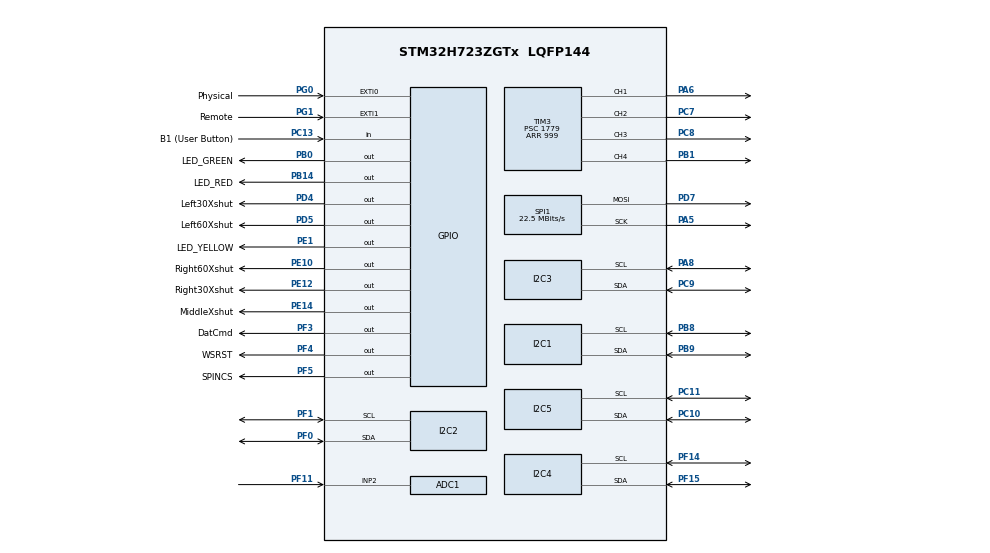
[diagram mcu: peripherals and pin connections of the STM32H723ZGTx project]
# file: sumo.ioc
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ADC1.Channel-0\#ChannelRegularConversion=ADC_CHANNEL_2
ADC1.NbrOfConversionFlag=1
ADC1.OffsetNumber-0\#ChannelRegularConversion=ADC_OFFSET_NONE
ADC1.OffsetSignedSaturation-0\#ChannelRegularConversion=DISABLE
ADC1.Rank-0\#ChannelRegularConversion=1
ADC1.SamplingTime-0\#ChannelRegularConversion=ADC_SAMPLETIME_1CYCLE_5
ADC1.master=1
CORTEX_M7.default_mode_Activation=1
I2C1.Timing=0x207077AF
I2C2.Timing=0x207077AF
I2C3.Timing=0x207077AF
I2C4.Timing=0x207077AF
I2C5.Timing=0x207077AF
Mcu.Family=STM32H7
Mcu.Name=STM32H723ZGTx
Mcu.Package=LQFP144
NVIC.ADC_IRQn=true\:0\:0\:false\:false\:true\:true\:true\:true
NVIC.EXTI0_IRQn=true\:0\:0\:false\:false\:true\:true\:true\:true
NVIC.EXTI1_IRQn=true\:0\:0\:false\:false\:true\:true\:true\:true
NVIC.PriorityGroup=NVIC_PRIORITYGROUP_4
PA13(JTMS/SWDIO).GPIO_Label=SWDIO
PA13(JTMS/SWDIO).Signal=DEBUG_JTMS-SWDIO
PA14(JTCK/SWCLK).GPIO_Label=SWCLK
PA14(JTCK/SWCLK).Signal=DEBUG_JTCK-SWCLK
PA5.Mode=TX_Only_Simplex_Unidirect_Master
PA5.Signal=SPI1_SCK
PA6.Signal=S_TIM3_CH1
PA8.Mode=I2C
PA8.Signal=I2C3_SCL
PB0.GPIO_Label=LED_GREEN
PB0.Signal=GPIO_Output
PB1.Signal=S_TIM3_CH4
PB14.GPIO_Label=LED_RED
PB14.Signal=GPIO_Output
PB8.Mode=I2C
PB8.Signal=I2C1_SCL
PB9.Mode=I2C
PB9.Signal=I2C1_SDA
PC10.Mode=I2C
PC10.Signal=I2C5_SDA
PC11.Mode=I2C
PC11.Signal=I2C5_SCL
PC13.GPIO_Label=B1 (User Button)
PC13.Signal=GPIO_Input
PC14-OSC32_IN.Signal=RCC_OSC32_IN
PC15-OSC32_OUT.Signal=RCC_OSC32_OUT
PC7.Signal=S_TIM3_CH2
PC8.Signal=S_TIM3_CH3
PC9.Mode=I2C
PC9.Signal=I2C3_SDA
PD4.GPIO_Label=Left30Xshut
PD4.PinState=GPIO_PIN_SET
PD4.Signal=GPIO_Output
PD5.GPIO_Label=Left60Xshut
PD5.PinState=GPIO_PIN_SET
PD5.Signal=GPIO_Output
PD7.Mode=TX_Only_Simplex_Unidirect_Master
PD7.Signal=SPI1_MOSI
PD8.GPIO_Label=STLK_VCP_RX
PD8.Signal=USART3_TX
PD9.GPIO_Label=STLK_VCP_TX
PD9.Signal=USART3_RX
PE1.GPIO_Label=LED_YELLOW
PE1.Signal=GPIO_Output
PE10.GPIO_Label=Right60Xshut
PE10.PinState=GPIO_PIN_SET
PE10.Signal=GPIO_Output
PE12.GPIO_Label=Right30Xshut
PE12.PinState=GPIO_PIN_SET
PE12.Signal=GPIO_Output
PE14.GPIO_Label=MiddleXshut
PE14.PinState=GPIO_PIN_SET
PE14.Signal=GPIO_Output
PF0.Mode=I2C
PF0.Signal=I2C2_SDA
PF1.Mode=I2C
PF1.Signal=I2C2_SCL
PF11.Mode=IN2-Single-Ended
PF11.Signal=ADC1_INP2
PF14.Mode=I2C
PF14.Signal=I2C4_SCL
PF15.Mode=I2C
PF15.Signal=I2C4_SDA
PF3.GPIO_Label=DatCmd
PF3.Signal=GPIO_Output
PF4.GPIO_Label=WSRST
PF4.Signal=GPIO_Output
PF5.GPIO_Label=SPINCS
PF5.Signal=GPIO_Output
PG0.GPIO_Label=Physical
PG0.GPIO_ModeDefaultEXTI=GPIO_MODE_IT_FALLING
PG0.GPIO_PuPd=GPIO_PULLDOWN
PG0.Signal=GPXTI0
PG1.GPIO_Label=Remote
PG1.GPIO_ModeDefaultEXTI=GPIO_MODE_IT_RISING_FALLING
PG1.GPIO_PuPd=GPIO_PULLDOWN
PG1.Signal=GPXTI1
PH0-OSC_IN.Mode=HSE-External-Oscillator
PH0-OSC_IN.Signal=RCC_OSC_IN
PH1-OSC_OUT.Mode=HSE-External-Oscillator
PH1-OSC_OUT.Signal=RCC_OSC_OUT
ProjectManager.HeapSize=0x200
ProjectManager.StackSize=0x400
ProjectManager.TargetToolchain=STM32CubeIDE
RCC.ADCFreq_Value=10000000
RCC.APB1Freq_Value=90000000
RCC.APB2Freq_Value=90000000
RCC.APB3Freq_Value=90000000
RCC.APB4Freq_Value=90000000
RCC.CortexFreq_Value=360000000
RCC.D1PPRE=RCC_APB3_DIV2
RCC.D2PPRE1=RCC_APB1_DIV2
RCC.D2PPRE2=RCC_APB2_DIV2
RCC.D3PPRE=RCC_APB4_DIV2
RCC.DIVM1=1
RCC.DIVM2=1
RCC.DIVN1=45
RCC.DIVN2=25
RCC.DIVP1=1
RCC.DIVP2=20
RCC.HCLKFreq_Value=180000000
RCC.HPRE=RCC_HCLK_DIV2
RCC.HSE_VALUE=8000000
RCC.PLL2FRACN=0
RCC.PLLFRACN=0
RCC.PLLSourceVirtual=RCC_PLLSOURCE_HSE
RCC.SYSCLKFreq_VALUE=360000000
RCC.SYSCLKSource=RCC_SYSCLKSOURCE_PLLCLK
RCC.USBCLockSelection=RCC_USBCLKSOURCE_HSI48
RCC.USBFreq_Value=48000000
SH.S_TIM3_CH1.0=TIM3_CH1,PWM Generation1 CH1
SH.S_TIM3_CH2.0=TIM3_CH2,PWM Generation2 CH2
SH.S_TIM3_CH3.0=TIM3_CH3,PWM Generation3 CH3
SH.S_TIM3_CH4.0=TIM3_CH4,PWM Generation4 CH4
SPI1.BaudRatePrescaler=SPI_BAUDRATEPRESCALER_8
SPI1.CalculateBaudRate=22.5 MBits/s
SPI1.DataSize=SPI_DATASIZE_8BIT
SPI1.Direction=SPI_DIRECTION_2LINES_TXONLY
SPI1.Mode=SPI_MODE_MASTER
SPI1.VirtualType=VM_MASTER
TIM3.Channel-PWM\ Generation1\ CH1=TIM_CHANNEL_1
TIM3.Channel-PWM\ Generation2\ CH2=TIM_CHANNEL_2
TIM3.Channel-PWM\ Generation3\ CH3=TIM_CHANNEL_3
TIM3.Channel-PWM\ Generation4\ CH4=TIM_CHANNEL_4
TIM3.Period=999
TIM3.Prescaler=1779
VP_MEMORYMAP_VS_MEMORYMAP.Mode=CurAppReg
VP_TIM3_VS_ClockSourceINT.Mode=Internal
board=NUCLEO-H723ZG

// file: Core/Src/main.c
/* USER CODE BEGIN Header */
/**
  ******************************************************************************
  * @file           : main.c
  * @brief          : Main program body
  ******************************************************************************
  * @attention
  *
  * Copyright (c) 2025 STMicroelectronics.
  * All rights reserved.
  *
  * This software is licensed under terms that can be found in the LICENSE file
  * in the root directory of this software component.
  * If no LICENSE file comes with this software, it is provided AS-IS.
  *
  ******************************************************************************
  */
/* USER CODE END Header */
#include "main.h"

/* USER CODE BEGIN PTD */
#include "../Repo/Inc/cpp_main.h"
/* USER CODE END PTD */

I2C_HandleTypeDef hi2c1;
I2C_HandleTypeDef hi2c2;
I2C_HandleTypeDef hi2c3;
I2C_HandleTypeDef hi2c4;
I2C_HandleTypeDef hi2c5;

SPI_HandleTypeDef hspi1;

void SystemClock_Config(void);
static void MPU_Config(void);
static void MX_GPIO_Init(void);
static void MX_ADC1_Init(void);
static void MX_I2C1_Init(void);
static void MX_I2C2_Init(void);
static void MX_I2C3_Init(void);
static void MX_I2C4_Init(void);
static void MX_I2C5_Init(void);
static void MX_SPI1_Init(void);
static void MX_TIM3_Init(void);

int main(void)
{

  /* MPU Configuration--------------------------------------------------------*/
  MPU_Config();

  /* MCU Configuration--------------------------------------------------------*/

  /* Reset of all peripherals, Initializes the Flash interface and the Systick. */
  HAL_Init();

  /* Configure the system clock */
  SystemClock_Config();

  /* Initialize all configured peripherals */
  MX_GPIO_Init();
  MX_ADC1_Init();
  MX_I2C1_Init();
  MX_I2C2_Init();
  MX_I2C3_Init();
  MX_I2C4_Init();
  MX_I2C5_Init();
  MX_SPI1_Init();
  MX_TIM3_Init();

  /* Infinite loop */
  /* USER CODE BEGIN WHILE */
  main_cpp_loop();
  while (1)
  {
    /* USER CODE END WHILE */

  }
}

void SystemClock_Config(void)
{
  RCC_OscInitTypeDef RCC_OscInitStruct = {0};
  RCC_ClkInitTypeDef RCC_ClkInitStruct = {0};

  /** Supply configuration update enable
  */
  HAL_PWREx_ConfigSupply(PWR_LDO_SUPPLY);

  /** Configure the main internal regulator output voltage
  */
  __HAL_PWR_VOLTAGESCALING_CONFIG(PWR_REGULATOR_VOLTAGE_SCALE1);

  while(!__HAL_PWR_GET_FLAG(PWR_FLAG_VOSRDY)) {}

  /** Initializes the RCC Oscillators according to the specified parameters
  * in the RCC_OscInitTypeDef structure.
  */
  RCC_OscInitStruct.OscillatorType = RCC_OSCILLATORTYPE_HSE;
  RCC_OscInitStruct.HSEState = RCC_HSE_ON;
  RCC_OscInitStruct.PLL.PLLState = RCC_PLL_ON;
  RCC_OscInitStruct.PLL.PLLSource = RCC_PLLSOURCE_HSE;
  RCC_OscInitStruct.PLL.PLLM = 1;
  RCC_OscInitStruct.PLL.PLLN = 45;
  RCC_OscInitStruct.PLL.PLLP = 1;
  RCC_OscInitStruct.PLL.PLLQ = 2;
  RCC_OscInitStruct.PLL.PLLR = 2;
  RCC_OscInitStruct.PLL.PLLRGE = RCC_PLL1VCIRANGE_3;
  RCC_OscInitStruct.PLL.PLLVCOSEL = RCC_PLL1VCOWIDE;
  RCC_OscInitStruct.PLL.PLLFRACN = 0;
  if (HAL_RCC_OscConfig(&RCC_OscInitStruct) != HAL_OK)
  {
    Error_Handler();
  }

  /** Initializes the CPU, AHB and APB buses clocks
  */
  RCC_ClkInitStruct.ClockType = RCC_CLOCKTYPE_HCLK|RCC_CLOCKTYPE_SYSCLK
                              |RCC_CLOCKTYPE_PCLK1|RCC_CLOCKTYPE_PCLK2
                              |RCC_CLOCKTYPE_D3PCLK1|RCC_CLOCKTYPE_D1PCLK1;
  RCC_ClkInitStruct.SYSCLKSource = RCC_SYSCLKSOURCE_PLLCLK;
  RCC_ClkInitStruct.SYSCLKDivider = RCC_SYSCLK_DIV1;
  RCC_ClkInitStruct.AHBCLKDivider = RCC_HCLK_DIV2;
  RCC_ClkInitStruct.APB3CLKDivider = RCC_APB3_DIV2;
  RCC_ClkInitStruct.APB1CLKDivider = RCC_APB1_DIV2;
  RCC_ClkInitStruct.APB2CLKDivider = RCC_APB2_DIV2;
  RCC_ClkInitStruct.APB4CLKDivider = RCC_APB4_DIV2;

  if (HAL_RCC_ClockConfig(&RCC_ClkInitStruct, FLASH_LATENCY_2) != HAL_OK)
  {
    Error_Handler();
  }
}

static void MX_ADC1_Init(void)
{

  LL_ADC_InitTypeDef ADC_InitStruct = {0};
  LL_ADC_REG_InitTypeDef ADC_REG_InitStruct = {0};
  LL_ADC_CommonInitTypeDef ADC_CommonInitStruct = {0};

  LL_GPIO_InitTypeDef GPIO_InitStruct = {0};
  RCC_PeriphCLKInitTypeDef PeriphClkInitStruct = {0};

  /** Initializes the peripherals clock
  */
  PeriphClkInitStruct.PeriphClockSelection = RCC_PERIPHCLK_ADC;
  PeriphClkInitStruct.PLL2.PLL2M = 1;
  PeriphClkInitStruct.PLL2.PLL2N = 25;
  PeriphClkInitStruct.PLL2.PLL2P = 20;
  PeriphClkInitStruct.PLL2.PLL2Q = 2;
  PeriphClkInitStruct.PLL2.PLL2R = 2;
  PeriphClkInitStruct.PLL2.PLL2RGE = RCC_PLL2VCIRANGE_3;
  PeriphClkInitStruct.PLL2.PLL2VCOSEL = RCC_PLL2VCOWIDE;
  PeriphClkInitStruct.PLL2.PLL2FRACN = 0.0;
  PeriphClkInitStruct.AdcClockSelection = RCC_ADCCLKSOURCE_PLL2;
  if (HAL_RCCEx_PeriphCLKConfig(&PeriphClkInitStruct) != HAL_OK)
  {
    Error_Handler();
  }

  /* Peripheral clock enable */
  LL_AHB1_GRP1_EnableClock(LL_AHB1_GRP1_PERIPH_ADC12);

  LL_AHB4_GRP1_EnableClock(LL_AHB4_GRP1_PERIPH_GPIOF);
  /**ADC1 GPIO Configuration
  PF11   ------> ADC1_INP2
  */
  GPIO_InitStruct.Pin = LL_GPIO_PIN_11;
  GPIO_InitStruct.Mode = LL_GPIO_MODE_ANALOG;
  GPIO_InitStruct.Pull = LL_GPIO_PULL_NO;
  LL_GPIO_Init(GPIOF, &GPIO_InitStruct);

  /* ADC1 interrupt Init */
  NVIC_SetPriority(ADC_IRQn, NVIC_EncodePriority(NVIC_GetPriorityGrouping(),0, 0));
  NVIC_EnableIRQ(ADC_IRQn);

  /** Common config
  */
  LL_ADC_SetOverSamplingScope(ADC1, LL_ADC_OVS_DISABLE);
  ADC_InitStruct.Resolution = LL_ADC_RESOLUTION_16B;
  ADC_InitStruct.LowPowerMode = LL_ADC_LP_MODE_NONE;
  LL_ADC_Init(ADC1, &ADC_InitStruct);
  ADC_REG_InitStruct.TriggerSource = LL_ADC_REG_TRIG_SOFTWARE;
  ADC_REG_InitStruct.SequencerLength = LL_ADC_REG_SEQ_SCAN_DISABLE;
  ADC_REG_InitStruct.SequencerDiscont = DISABLE;
  ADC_REG_InitStruct.ContinuousMode = LL_ADC_REG_CONV_SINGLE;
  ADC_REG_InitStruct.Overrun = LL_ADC_REG_OVR_DATA_PRESERVED;
  LL_ADC_REG_Init(ADC1, &ADC_REG_InitStruct);
  LL_ADC_REG_SetDataTransferMode(ADC1, LL_ADC_REG_DR_TRANSFER);
  ADC_CommonInitStruct.CommonClock = LL_ADC_CLOCK_ASYNC_DIV1;
  ADC_CommonInitStruct.Multimode = LL_ADC_MULTI_INDEPENDENT;
  LL_ADC_CommonInit(__LL_ADC_COMMON_INSTANCE(ADC1), &ADC_CommonInitStruct);

  /* Disable ADC deep power down (enabled by default after reset state) */
  LL_ADC_DisableDeepPowerDown(ADC1);
  /* Enable ADC internal voltage regulator */
  LL_ADC_EnableInternalRegulator(ADC1);
  /* Delay for ADC internal voltage regulator stabilization. */
  /* Compute number of CPU cycles to wait for, from delay in us. */
  /* Note: Variable divided by 2 to compensate partially */
  /* CPU processing cycles (depends on compilation optimization). */
  /* Note: If system core clock frequency is below 200kHz, wait time */
  /* is only a few CPU processing cycles. */
  __IO uint32_t wait_loop_index;
  wait_loop_index = ((LL_ADC_DELAY_INTERNAL_REGUL_STAB_US * (SystemCoreClock / (100000 * 2))) / 10);
  while(wait_loop_index != 0)
  {
    wait_loop_index--;
  }

  /** Configure Regular Channel
  */
  LL_ADC_REG_SetSequencerRanks(ADC1, LL_ADC_REG_RANK_1, LL_ADC_CHANNEL_2);
  LL_ADC_SetChannelSamplingTime(ADC1, LL_ADC_CHANNEL_2, LL_ADC_SAMPLINGTIME_1CYCLE_5);
  LL_ADC_SetChannelSingleDiff(ADC1, LL_ADC_CHANNEL_2, LL_ADC_SINGLE_ENDED);
  LL_ADC_SetChannelPreselection(ADC1, LL_ADC_CHANNEL_2);

}

static void MX_I2C1_Init(void)
{

  hi2c1.Instance = I2C1;
  hi2c1.Init.Timing = 0x207077AF;
  hi2c1.Init.OwnAddress1 = 0;
  hi2c1.Init.AddressingMode = I2C_ADDRESSINGMODE_7BIT;
  hi2c1.Init.DualAddressMode = I2C_DUALADDRESS_DISABLE;
  hi2c1.Init.OwnAddress2 = 0;
  hi2c1.Init.OwnAddress2Masks = I2C_OA2_NOMASK;
  hi2c1.Init.GeneralCallMode = I2C_GENERALCALL_DISABLE;
  hi2c1.Init.NoStretchMode = I2C_NOSTRETCH_DISABLE;
  if (HAL_I2C_Init(&hi2c1) != HAL_OK)
  {
    Error_Handler();
  }

  /** Configure Analogue filter
  */
  if (HAL_I2CEx_ConfigAnalogFilter(&hi2c1, I2C_ANALOGFILTER_ENABLE) != HAL_OK)
  {
    Error_Handler();
  }

  /** Configure Digital filter
  */
  if (HAL_I2CEx_ConfigDigitalFilter(&hi2c1, 0) != HAL_OK)
  {
    Error_Handler();
  }

}

static void MX_I2C2_Init(void)
{

  hi2c2.Instance = I2C2;
  hi2c2.Init.Timing = 0x207077AF;
  hi2c2.Init.OwnAddress1 = 0;
  hi2c2.Init.AddressingMode = I2C_ADDRESSINGMODE_7BIT;
  hi2c2.Init.DualAddressMode = I2C_DUALADDRESS_DISABLE;
  hi2c2.Init.OwnAddress2 = 0;
  hi2c2.Init.OwnAddress2Masks = I2C_OA2_NOMASK;
  hi2c2.Init.GeneralCallMode = I2C_GENERALCALL_DISABLE;
  hi2c2.Init.NoStretchMode = I2C_NOSTRETCH_DISABLE;
  if (HAL_I2C_Init(&hi2c2) != HAL_OK)
  {
    Error_Handler();
  }

  /** Configure Analogue filter
  */
  if (HAL_I2CEx_ConfigAnalogFilter(&hi2c2, I2C_ANALOGFILTER_ENABLE) != HAL_OK)
  {
    Error_Handler();
  }

  /** Configure Digital filter
  */
  if (HAL_I2CEx_ConfigDigitalFilter(&hi2c2, 0) != HAL_OK)
  {
    Error_Handler();
  }

}

static void MX_I2C3_Init(void)
{

  hi2c3.Instance = I2C3;
  hi2c3.Init.Timing = 0x207077AF;
  hi2c3.Init.OwnAddress1 = 0;
  hi2c3.Init.AddressingMode = I2C_ADDRESSINGMODE_7BIT;
  hi2c3.Init.DualAddressMode = I2C_DUALADDRESS_DISABLE;
  hi2c3.Init.OwnAddress2 = 0;
  hi2c3.Init.OwnAddress2Masks = I2C_OA2_NOMASK;
  hi2c3.Init.GeneralCallMode = I2C_GENERALCALL_DISABLE;
  hi2c3.Init.NoStretchMode = I2C_NOSTRETCH_DISABLE;
  if (HAL_I2C_Init(&hi2c3) != HAL_OK)
  {
    Error_Handler();
  }

  /** Configure Analogue filter
  */
  if (HAL_I2CEx_ConfigAnalogFilter(&hi2c3, I2C_ANALOGFILTER_ENABLE) != HAL_OK)
  {
    Error_Handler();
  }

  /** Configure Digital filter
  */
  if (HAL_I2CEx_ConfigDigitalFilter(&hi2c3, 0) != HAL_OK)
  {
    Error_Handler();
  }

}

static void MX_I2C4_Init(void)
{

  hi2c4.Instance = I2C4;
  hi2c4.Init.Timing = 0x207077AF;
  hi2c4.Init.OwnAddress1 = 0;
  hi2c4.Init.AddressingMode = I2C_ADDRESSINGMODE_7BIT;
  hi2c4.Init.DualAddressMode = I2C_DUALADDRESS_DISABLE;
  hi2c4.Init.OwnAddress2 = 0;
  hi2c4.Init.OwnAddress2Masks = I2C_OA2_NOMASK;
  hi2c4.Init.GeneralCallMode = I2C_GENERALCALL_DISABLE;
  hi2c4.Init.NoStretchMode = I2C_NOSTRETCH_DISABLE;
  if (HAL_I2C_Init(&hi2c4) != HAL_OK)
  {
    Error_Handler();
  }

  /** Configure Analogue filter
  */
  if (HAL_I2CEx_ConfigAnalogFilter(&hi2c4, I2C_ANALOGFILTER_ENABLE) != HAL_OK)
  {
    Error_Handler();
  }

  /** Configure Digital filter
  */
  if (HAL_I2CEx_ConfigDigitalFilter(&hi2c4, 0) != HAL_OK)
  {
    Error_Handler();
  }

}

static void MX_I2C5_Init(void)
{

  hi2c5.Instance = I2C5;
  hi2c5.Init.Timing = 0x207077AF;
  hi2c5.Init.OwnAddress1 = 0;
  hi2c5.Init.AddressingMode = I2C_ADDRESSINGMODE_7BIT;
  hi2c5.Init.DualAddressMode = I2C_DUALADDRESS_DISABLE;
  hi2c5.Init.OwnAddress2 = 0;
  hi2c5.Init.OwnAddress2Masks = I2C_OA2_NOMASK;
  hi2c5.Init.GeneralCallMode = I2C_GENERALCALL_DISABLE;
  hi2c5.Init.NoStretchMode = I2C_NOSTRETCH_DISABLE;
  if (HAL_I2C_Init(&hi2c5) != HAL_OK)
  {
    Error_Handler();
  }

  /** Configure Analogue filter
  */
  if (HAL_I2CEx_ConfigAnalogFilter(&hi2c5, I2C_ANALOGFILTER_ENABLE) != HAL_OK)
  {
    Error_Handler();
  }

  /** Configure Digital filter
  */
  if (HAL_I2CEx_ConfigDigitalFilter(&hi2c5, 0) != HAL_OK)
  {
    Error_Handler();
  }

}

static void MX_SPI1_Init(void)
{

  /* SPI1 parameter configuration*/
  hspi1.Instance = SPI1;
  hspi1.Init.Mode = SPI_MODE_MASTER;
  hspi1.Init.Direction = SPI_DIRECTION_2LINES_TXONLY;
  hspi1.Init.DataSize = SPI_DATASIZE_8BIT;
  hspi1.Init.CLKPolarity = SPI_POLARITY_LOW;
  hspi1.Init.CLKPhase = SPI_PHASE_1EDGE;
  hspi1.Init.NSS = SPI_NSS_SOFT;
  hspi1.Init.BaudRatePrescaler = SPI_BAUDRATEPRESCALER_8;
  hspi1.Init.FirstBit = SPI_FIRSTBIT_MSB;
  hspi1.Init.TIMode = SPI_TIMODE_DISABLE;
  hspi1.Init.CRCCalculation = SPI_CRCCALCULATION_DISABLE;
  hspi1.Init.CRCPolynomial = 0x0;
  hspi1.Init.NSSPMode = SPI_NSS_PULSE_ENABLE;
  hspi1.Init.NSSPolarity = SPI_NSS_POLARITY_LOW;
  hspi1.Init.FifoThreshold = SPI_FIFO_THRESHOLD_01DATA;
  hspi1.Init.TxCRCInitializationPattern = SPI_CRC_INITIALIZATION_ALL_ZERO_PATTERN;
  hspi1.Init.RxCRCInitializationPattern = SPI_CRC_INITIALIZATION_ALL_ZERO_PATTERN;
  hspi1.Init.MasterSSIdleness = SPI_MASTER_SS_IDLENESS_00CYCLE;
  hspi1.Init.MasterInterDataIdleness = SPI_MASTER_INTERDATA_IDLENESS_00CYCLE;
  hspi1.Init.MasterReceiverAutoSusp = SPI_MASTER_RX_AUTOSUSP_DISABLE;
  hspi1.Init.MasterKeepIOState = SPI_MASTER_KEEP_IO_STATE_DISABLE;
  hspi1.Init.IOSwap = SPI_IO_SWAP_DISABLE;
  if (HAL_SPI_Init(&hspi1) != HAL_OK)
  {
    Error_Handler();
  }

}

static void MX_TIM3_Init(void)
{

  LL_TIM_InitTypeDef TIM_InitStruct = {0};
  LL_TIM_OC_InitTypeDef TIM_OC_InitStruct = {0};

  LL_GPIO_InitTypeDef GPIO_InitStruct = {0};

  /* Peripheral clock enable */
  LL_APB1_GRP1_EnableClock(LL_APB1_GRP1_PERIPH_TIM3);

  TIM_InitStruct.Prescaler = 1779;
  TIM_InitStruct.CounterMode = LL_TIM_COUNTERMODE_UP;
  TIM_InitStruct.Autoreload = 999;
  TIM_InitStruct.ClockDivision = LL_TIM_CLOCKDIVISION_DIV1;
  LL_TIM_Init(TIM3, &TIM_InitStruct);
  LL_TIM_DisableARRPreload(TIM3);
  LL_TIM_SetClockSource(TIM3, LL_TIM_CLOCKSOURCE_INTERNAL);
  LL_TIM_OC_EnablePreload(TIM3, LL_TIM_CHANNEL_CH1);
  TIM_OC_InitStruct.OCMode = LL_TIM_OCMODE_PWM1;
  TIM_OC_InitStruct.OCState = LL_TIM_OCSTATE_DISABLE;
  TIM_OC_InitStruct.OCNState = LL_TIM_OCSTATE_DISABLE;
  TIM_OC_InitStruct.CompareValue = 0;
  TIM_OC_InitStruct.OCPolarity = LL_TIM_OCPOLARITY_HIGH;
  LL_TIM_OC_Init(TIM3, LL_TIM_CHANNEL_CH1, &TIM_OC_InitStruct);
  LL_TIM_OC_DisableFast(TIM3, LL_TIM_CHANNEL_CH1);
  LL_TIM_OC_EnablePreload(TIM3, LL_TIM_CHANNEL_CH2);
  LL_TIM_OC_Init(TIM3, LL_TIM_CHANNEL_CH2, &TIM_OC_InitStruct);
  LL_TIM_OC_DisableFast(TIM3, LL_TIM_CHANNEL_CH2);
  LL_TIM_OC_EnablePreload(TIM3, LL_TIM_CHANNEL_CH3);
  LL_TIM_OC_Init(TIM3, LL_TIM_CHANNEL_CH3, &TIM_OC_InitStruct);
  LL_TIM_OC_DisableFast(TIM3, LL_TIM_CHANNEL_CH3);
  LL_TIM_OC_EnablePreload(TIM3, LL_TIM_CHANNEL_CH4);
  LL_TIM_OC_Init(TIM3, LL_TIM_CHANNEL_CH4, &TIM_OC_InitStruct);
  LL_TIM_OC_DisableFast(TIM3, LL_TIM_CHANNEL_CH4);
  LL_TIM_SetTriggerOutput(TIM3, LL_TIM_TRGO_RESET);
  LL_TIM_DisableMasterSlaveMode(TIM3);
  LL_AHB4_GRP1_EnableClock(LL_AHB4_GRP1_PERIPH_GPIOA);
  LL_AHB4_GRP1_EnableClock(LL_AHB4_GRP1_PERIPH_GPIOB);
  LL_AHB4_GRP1_EnableClock(LL_AHB4_GRP1_PERIPH_GPIOC);
  /**TIM3 GPIO Configuration
  PA6   ------> TIM3_CH1
  PB1   ------> TIM3_CH4
  PC7   ------> TIM3_CH2
  PC8   ------> TIM3_CH3
  */
  GPIO_InitStruct.Pin = LL_GPIO_PIN_6;
  GPIO_InitStruct.Mode = LL_GPIO_MODE_ALTERNATE;
  GPIO_InitStruct.Speed = LL_GPIO_SPEED_FREQ_LOW;
  GPIO_InitStruct.OutputType = LL_GPIO_OUTPUT_PUSHPULL;
  GPIO_InitStruct.Pull = LL_GPIO_PULL_NO;
  GPIO_InitStruct.Alternate = LL_GPIO_AF_2;
  LL_GPIO_Init(GPIOA, &GPIO_InitStruct);

  GPIO_InitStruct.Pin = LL_GPIO_PIN_1;
  GPIO_InitStruct.Mode = LL_GPIO_MODE_ALTERNATE;
  GPIO_InitStruct.Speed = LL_GPIO_SPEED_FREQ_LOW;
  GPIO_InitStruct.OutputType = LL_GPIO_OUTPUT_PUSHPULL;
  GPIO_InitStruct.Pull = LL_GPIO_PULL_NO;
  GPIO_InitStruct.Alternate = LL_GPIO_AF_2;
  LL_GPIO_Init(GPIOB, &GPIO_InitStruct);

  GPIO_InitStruct.Pin = LL_GPIO_PIN_7|LL_GPIO_PIN_8;
  GPIO_InitStruct.Mode = LL_GPIO_MODE_ALTERNATE;
  GPIO_InitStruct.Speed = LL_GPIO_SPEED_FREQ_LOW;
  GPIO_InitStruct.OutputType = LL_GPIO_OUTPUT_PUSHPULL;
  GPIO_InitStruct.Pull = LL_GPIO_PULL_NO;
  GPIO_InitStruct.Alternate = LL_GPIO_AF_2;
  LL_GPIO_Init(GPIOC, &GPIO_InitStruct);

}

static void MX_GPIO_Init(void)
{
  GPIO_InitTypeDef GPIO_InitStruct = {0};

  /* GPIO Ports Clock Enable */
  __HAL_RCC_GPIOC_CLK_ENABLE();
  __HAL_RCC_GPIOF_CLK_ENABLE();
  __HAL_RCC_GPIOH_CLK_ENABLE();
  __HAL_RCC_GPIOA_CLK_ENABLE();
  __HAL_RCC_GPIOB_CLK_ENABLE();
  __HAL_RCC_GPIOG_CLK_ENABLE();
  __HAL_RCC_GPIOE_CLK_ENABLE();
  __HAL_RCC_GPIOD_CLK_ENABLE();

  /*Configure GPIO pin Output Level */
  HAL_GPIO_WritePin(GPIOF, DatCmd_Pin|WSRST_Pin|SPINCS_Pin, GPIO_PIN_RESET);

  /*Configure GPIO pin Output Level */
  HAL_GPIO_WritePin(GPIOB, LED_GREEN_Pin|LED_RED_Pin, GPIO_PIN_RESET);

  /*Configure GPIO pin Output Level */
  HAL_GPIO_WritePin(GPIOE, Right60Xshut_Pin|Right30Xshut_Pin|MiddleXshut_Pin, GPIO_PIN_SET);

  /*Configure GPIO pin Output Level */
  HAL_GPIO_WritePin(GPIOD, Left30Xshut_Pin|Left60Xshut_Pin, GPIO_PIN_SET);

  /*Configure GPIO pin Output Level */
  HAL_GPIO_WritePin(LED_YELLOW_GPIO_Port, LED_YELLOW_Pin, GPIO_PIN_RESET);

  /*Configure GPIO pin : B1_Pin */
  GPIO_InitStruct.Pin = B1_Pin;
  GPIO_InitStruct.Mode = GPIO_MODE_INPUT;
  GPIO_InitStruct.Pull = GPIO_NOPULL;
  HAL_GPIO_Init(B1_GPIO_Port, &GPIO_InitStruct);

  /*Configure GPIO pins : DatCmd_Pin WSRST_Pin SPINCS_Pin */
  GPIO_InitStruct.Pin = DatCmd_Pin|WSRST_Pin|SPINCS_Pin;
  GPIO_InitStruct.Mode = GPIO_MODE_OUTPUT_PP;
  GPIO_InitStruct.Pull = GPIO_NOPULL;
  GPIO_InitStruct.Speed = GPIO_SPEED_FREQ_LOW;
  HAL_GPIO_Init(GPIOF, &GPIO_InitStruct);

  /*Configure GPIO pins : LED_GREEN_Pin LED_RED_Pin */
  GPIO_InitStruct.Pin = LED_GREEN_Pin|LED_RED_Pin;
  GPIO_InitStruct.Mode = GPIO_MODE_OUTPUT_PP;
  GPIO_InitStruct.Pull = GPIO_NOPULL;
  GPIO_InitStruct.Speed = GPIO_SPEED_FREQ_LOW;
  HAL_GPIO_Init(GPIOB, &GPIO_InitStruct);

  /*Configure GPIO pin : Physical_Pin */
  GPIO_InitStruct.Pin = Physical_Pin;
  GPIO_InitStruct.Mode = GPIO_MODE_IT_FALLING;
  GPIO_InitStruct.Pull = GPIO_PULLDOWN;
  HAL_GPIO_Init(Physical_GPIO_Port, &GPIO_InitStruct);

  /*Configure GPIO pin : Remote_Pin */
  GPIO_InitStruct.Pin = Remote_Pin;
  GPIO_InitStruct.Mode = GPIO_MODE_IT_RISING_FALLING;
  GPIO_InitStruct.Pull = GPIO_PULLDOWN;
  HAL_GPIO_Init(Remote_GPIO_Port, &GPIO_InitStruct);

  /*Configure GPIO pins : Right60Xshut_Pin Right30Xshut_Pin MiddleXshut_Pin LED_YELLOW_Pin */
  GPIO_InitStruct.Pin = Right60Xshut_Pin|Right30Xshut_Pin|MiddleXshut_Pin|LED_YELLOW_Pin;
  GPIO_InitStruct.Mode = GPIO_MODE_OUTPUT_PP;
  GPIO_InitStruct.Pull = GPIO_NOPULL;
  GPIO_InitStruct.Speed = GPIO_SPEED_FREQ_LOW;
  HAL_GPIO_Init(GPIOE, &GPIO_InitStruct);

  /*Configure GPIO pins : STLK_VCP_RX_Pin STLK_VCP_TX_Pin */
  GPIO_InitStruct.Pin = STLK_VCP_RX_Pin|STLK_VCP_TX_Pin;
  GPIO_InitStruct.Mode = GPIO_MODE_AF_PP;
  GPIO_InitStruct.Pull = GPIO_NOPULL;
  GPIO_InitStruct.Speed = GPIO_SPEED_FREQ_LOW;
  GPIO_InitStruct.Alternate = GPIO_AF7_USART3;
  HAL_GPIO_Init(GPIOD, &GPIO_InitStruct);

  /*Configure GPIO pins : Left30Xshut_Pin Left60Xshut_Pin */
  GPIO_InitStruct.Pin = Left30Xshut_Pin|Left60Xshut_Pin;
  GPIO_InitStruct.Mode = GPIO_MODE_OUTPUT_PP;
  GPIO_InitStruct.Pull = GPIO_NOPULL;
  GPIO_InitStruct.Speed = GPIO_SPEED_FREQ_LOW;
  HAL_GPIO_Init(GPIOD, &GPIO_InitStruct);

  /* EXTI interrupt init*/
  HAL_NVIC_SetPriority(Physical_EXTI_IRQn, 0, 0);
  HAL_NVIC_EnableIRQ(Physical_EXTI_IRQn);

  HAL_NVIC_SetPriority(Remote_EXTI_IRQn, 0, 0);
  HAL_NVIC_EnableIRQ(Remote_EXTI_IRQn);

}

 /* MPU Configuration */

void MPU_Config(void)
{
  MPU_Region_InitTypeDef MPU_InitStruct = {0};

  /* Disables the MPU */
  HAL_MPU_Disable();

  /** Initializes and configures the Region and the memory to be protected
  */
  MPU_InitStruct.Enable = MPU_REGION_ENABLE;
  MPU_InitStruct.Number = MPU_REGION_NUMBER0;
  MPU_InitStruct.BaseAddress = 0x0;
  MPU_InitStruct.Size = MPU_REGION_SIZE_4GB;
  MPU_InitStruct.SubRegionDisable = 0x87;
  MPU_InitStruct.TypeExtField = MPU_TEX_LEVEL0;
  MPU_InitStruct.AccessPermission = MPU_REGION_NO_ACCESS;
  MPU_InitStruct.DisableExec = MPU_INSTRUCTION_ACCESS_DISABLE;
  MPU_InitStruct.IsShareable = MPU_ACCESS_SHAREABLE;
  MPU_InitStruct.IsCacheable = MPU_ACCESS_NOT_CACHEABLE;
  MPU_InitStruct.IsBufferable = MPU_ACCESS_NOT_BUFFERABLE;

  HAL_MPU_ConfigRegion(&MPU_InitStruct);
  /* Enables the MPU */
  HAL_MPU_Enable(MPU_PRIVILEGED_DEFAULT);

}

void Error_Handler(void)
{
  __disable_irq();
  while (1)
  {
  }
}
